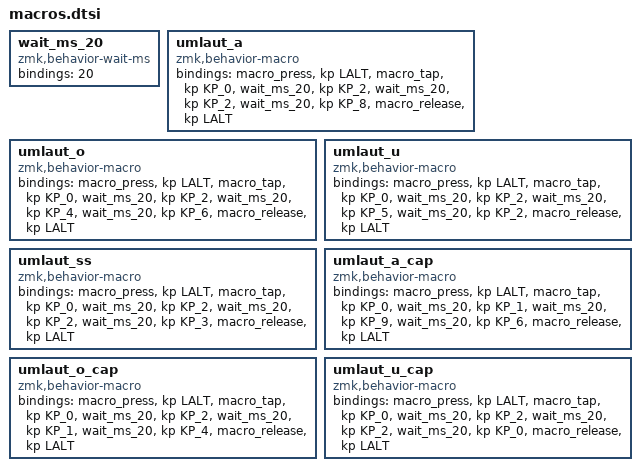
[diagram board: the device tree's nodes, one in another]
wait_ms_20: wait_ms_20 {
  compatible = "zmk,behavior-wait-ms";
  #binding-cells = <0>;
  bindings = <20>;
};

umlaut_a {
  compatible = "zmk,behavior-macro";
  #binding-cells = <0>;
  bindings = <
    &macro_press &kp LALT
    &macro_tap
      &kp KP_0 &wait_ms_20
      &kp KP_2 &wait_ms_20
      &kp KP_2 &wait_ms_20
      &kp KP_8
    &macro_release &kp LALT
  >;
};

umlaut_o {
  compatible = "zmk,behavior-macro";
  #binding-cells = <0>;
  bindings = <
    &macro_press &kp LALT
    &macro_tap
      &kp KP_0 &wait_ms_20
      &kp KP_2 &wait_ms_20
      &kp KP_4 &wait_ms_20
      &kp KP_6
    &macro_release &kp LALT
  >;
};

umlaut_u {
  compatible = "zmk,behavior-macro";
  #binding-cells = <0>;
  bindings = <
    &macro_press &kp LALT
    &macro_tap
      &kp KP_0 &wait_ms_20
      &kp KP_2 &wait_ms_20
      &kp KP_5 &wait_ms_20
      &kp KP_2
    &macro_release &kp LALT
  >;
};

umlaut_ss {
  compatible = "zmk,behavior-macro";
  #binding-cells = <0>;
  bindings = <
    &macro_press &kp LALT
    &macro_tap
      &kp KP_0 &wait_ms_20
      &kp KP_2 &wait_ms_20
      &kp KP_2 &wait_ms_20
      &kp KP_3
    &macro_release &kp LALT
  >;
};

umlaut_a_cap {
  compatible = "zmk,behavior-macro";
  #binding-cells = <0>;
  bindings = <
    &macro_press &kp LALT
    &macro_tap
      &kp KP_0 &wait_ms_20
      &kp KP_1 &wait_ms_20
      &kp KP_9 &wait_ms_20
      &kp KP_6
    &macro_release &kp LALT
  >;
};

umlaut_o_cap {
  compatible = "zmk,behavior-macro";
  #binding-cells = <0>;
  bindings = <
    &macro_press &kp LALT
    &macro_tap
      &kp KP_0 &wait_ms_20
      &kp KP_2 &wait_ms_20
      &kp KP_1 &wait_ms_20
      &kp KP_4
    &macro_release &kp LALT
  >;
};

umlaut_u_cap {
  compatible = "zmk,behavior-macro";
  #binding-cells = <0>;
  bindings = <
    &macro_press &kp LALT
    &macro_tap
      &kp KP_0 &wait_ms_20
      &kp KP_2 &wait_ms_20
      &kp KP_2 &wait_ms_20
      &kp KP_0
    &macro_release &kp LALT
  >;
};

